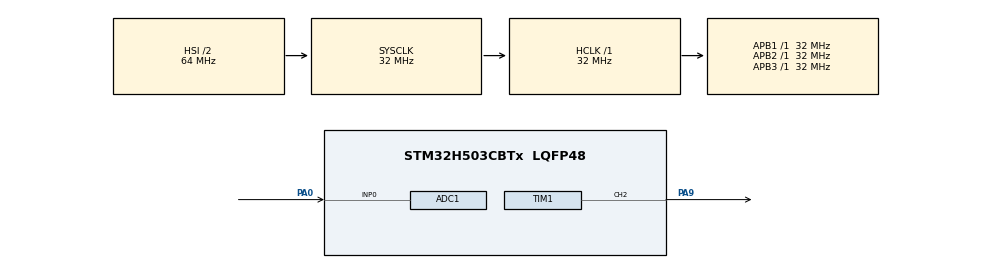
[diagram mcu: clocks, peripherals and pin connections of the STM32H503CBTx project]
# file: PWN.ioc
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ADC1.Channel-0\#ChannelRegularConversion=ADC_CHANNEL_0
ADC1.MonitoredBy-0\#ChannelRegularConversion=__NULL
ADC1.NbrOfConversionFlag=1
ADC1.OffsetNumber-0\#ChannelRegularConversion=ADC_OFFSET_NONE
ADC1.Rank-0\#ChannelRegularConversion=1
ADC1.SamplingTime-0\#ChannelRegularConversion=ADC_SAMPLETIME_2CYCLES_5
ADC1.master=1
Mcu.Family=STM32H5
Mcu.Name=STM32H503CBTx
Mcu.Package=LQFP48
NVIC.PriorityGroup=NVIC_PRIORITYGROUP_4
PA0.Signal=ADCx_INP0
PA9.Signal=S_TIM1_CH2
PH0-OSC_IN(PH0).Mode=HSE-External-Oscillator
PH0-OSC_IN(PH0).Signal=RCC_OSC_IN
PH1-OSC_OUT(PH1).Mode=HSE-External-Oscillator
PH1-OSC_OUT(PH1).Signal=RCC_OSC_OUT
ProjectManager.HeapSize=0x200
ProjectManager.StackSize=0x400
ProjectManager.TargetToolchain=STM32CubeIDE
RCC.ADCFreq_Value=32000000
RCC.AHBFreq_Value=32000000
RCC.APB1Freq_Value=32000000
RCC.APB1TimFreq_Value=32000000
RCC.APB2Freq_Value=32000000
RCC.APB2TimFreq_Value=32000000
RCC.APB3Freq_Value=32000000
RCC.CSI_VALUE=4000000
RCC.CortexFreq_Value=32000000
RCC.EPOD_VALUE=4000000
RCC.HCLKFreq_Value=32000000
RCC.HSE_VALUE=25000000
RCC.HSI48_VALUE=48000000
RCC.HSI_VALUE=64000000
RCC.LSE_VALUE=32768
RCC.LSIRC_VALUE=32000
RCC.SYSCLKFreq_VALUE=32000000
RCC.USBFreq_Value=48000000
RCC.VCOOutputFreq_Value=516000000
SH.ADCx_INP0.0=ADC1_INP0,IN0-Single-Ended
SH.S_TIM1_CH2.0=TIM1_CH2,PWM Generation2 CH2
TIM1.Channel-PWM\ Generation2\ CH2=TIM_CHANNEL_2
VP_BOOTPATH_VS_BOOTPATH.Mode=BP_Activate
VP_CORTEX_M33_NS_VS_Hclk.Mode=Hclk_Mode
VP_MEMORYMAP_VS_MEMORYMAP.Mode=CurAppReg
VP_PWR_VS_LPOM.Mode=PowerOptimisation
VP_PWR_VS_SECSignals.Mode=Security/Privilege
board=custom

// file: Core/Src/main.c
/* USER CODE BEGIN Header */
/**
  ******************************************************************************
  * @file           : main.c
  * @brief          : Main program body
  ******************************************************************************
  * @attention
  *
  * Copyright (c) 2025 STMicroelectronics.
  * All rights reserved.
  *
  * This software is licensed under terms that can be found in the LICENSE file
  * in the root directory of this software component.
  * If no LICENSE file comes with this software, it is provided AS-IS.
  *
  ******************************************************************************
  */
/* USER CODE END Header */
#include "main.h"

ADC_HandleTypeDef hadc1;

TIM_HandleTypeDef htim1;

/* USER CODE BEGIN PV */
uint32_t adc_value = 0;     // Значение АЦП (0-4095)
uint16_t pwm_duty = 0;      // Скважность ШИМ (0-999)
/* USER CODE END PV */

void SystemClock_Config(void);
static void MX_GPIO_Init(void);
static void MX_ADC1_Init(void);
static void MX_TIM1_Init(void);

int main(void)
{

  /* MCU Configuration--------------------------------------------------------*/

  /* Reset of all peripherals, Initializes the Flash interface and the Systick. */
  HAL_Init();

  /* Configure the system clock */
  SystemClock_Config();

  /* Initialize all configured peripherals */
  MX_GPIO_Init();
  MX_ADC1_Init();
  MX_TIM1_Init();
  /* USER CODE BEGIN 2 */

  HAL_TIM_PWM_Start(&htim1, TIM_CHANNEL_2);

  // Запускаем АЦП
  HAL_ADC_Start(&hadc1);

  /* USER CODE END 2 */

  /* Infinite loop */
  while (1)
  {

    /* USER CODE BEGIN 3 */

    HAL_ADC_Start(&hadc1);

    if (HAL_ADC_PollForConversion(&hadc1, 10) == HAL_OK)
    {
      //  значение АЦП
      adc_value = HAL_ADC_GetValue(&hadc1);

      //  АЦП (0-4095) в ШИМ (0-65535)
      pwm_duty = (adc_value * 65535) / 4095;

      //  скважность ШИМ
      __HAL_TIM_SET_COMPARE(&htim1, TIM_CHANNEL_2, pwm_duty);
    }

    HAL_Delay(10);
  }
  /* USER CODE END 3 */
}

void SystemClock_Config(void)
{
  RCC_OscInitTypeDef RCC_OscInitStruct = {0};
  RCC_ClkInitTypeDef RCC_ClkInitStruct = {0};

  /** Configure the main internal regulator output voltage
  */
  __HAL_PWR_VOLTAGESCALING_CONFIG(PWR_REGULATOR_VOLTAGE_SCALE3);

  while(!__HAL_PWR_GET_FLAG(PWR_FLAG_VOSRDY)) {}

  /** Initializes the RCC Oscillators according to the specified parameters
  * in the RCC_OscInitTypeDef structure.
  */
  RCC_OscInitStruct.OscillatorType = RCC_OSCILLATORTYPE_HSI;
  RCC_OscInitStruct.HSIState = RCC_HSI_ON;
  RCC_OscInitStruct.HSIDiv = RCC_HSI_DIV2;
  RCC_OscInitStruct.HSICalibrationValue = RCC_HSICALIBRATION_DEFAULT;
  RCC_OscInitStruct.PLL.PLLState = RCC_PLL_NONE;
  if (HAL_RCC_OscConfig(&RCC_OscInitStruct) != HAL_OK)
  {
    Error_Handler();
  }

  /** Initializes the CPU, AHB and APB buses clocks
  */
  RCC_ClkInitStruct.ClockType = RCC_CLOCKTYPE_HCLK|RCC_CLOCKTYPE_SYSCLK
                              |RCC_CLOCKTYPE_PCLK1|RCC_CLOCKTYPE_PCLK2
                              |RCC_CLOCKTYPE_PCLK3;
  RCC_ClkInitStruct.SYSCLKSource = RCC_SYSCLKSOURCE_HSI;
  RCC_ClkInitStruct.AHBCLKDivider = RCC_SYSCLK_DIV1;
  RCC_ClkInitStruct.APB1CLKDivider = RCC_HCLK_DIV1;
  RCC_ClkInitStruct.APB2CLKDivider = RCC_HCLK_DIV1;
  RCC_ClkInitStruct.APB3CLKDivider = RCC_HCLK_DIV1;

  if (HAL_RCC_ClockConfig(&RCC_ClkInitStruct, FLASH_LATENCY_1) != HAL_OK)
  {
    Error_Handler();
  }

  /** Configure the programming delay
  */
  __HAL_FLASH_SET_PROGRAM_DELAY(FLASH_PROGRAMMING_DELAY_0);
}

static void MX_ADC1_Init(void)
{

  ADC_ChannelConfTypeDef sConfig = {0};

  /** Common config
  */
  hadc1.Instance = ADC1;
  hadc1.Init.ClockPrescaler = ADC_CLOCK_ASYNC_DIV1;
  hadc1.Init.Resolution = ADC_RESOLUTION_12B;
  hadc1.Init.DataAlign = ADC_DATAALIGN_RIGHT;
  hadc1.Init.ScanConvMode = ADC_SCAN_DISABLE;
  hadc1.Init.EOCSelection = ADC_EOC_SINGLE_CONV;
  hadc1.Init.LowPowerAutoWait = DISABLE;
  hadc1.Init.ContinuousConvMode = DISABLE;
  hadc1.Init.NbrOfConversion = 1;
  hadc1.Init.DiscontinuousConvMode = DISABLE;
  hadc1.Init.ExternalTrigConv = ADC_SOFTWARE_START;
  hadc1.Init.ExternalTrigConvEdge = ADC_EXTERNALTRIGCONVEDGE_NONE;
  hadc1.Init.DMAContinuousRequests = DISABLE;
  hadc1.Init.SamplingMode = ADC_SAMPLING_MODE_NORMAL;
  hadc1.Init.Overrun = ADC_OVR_DATA_PRESERVED;
  hadc1.Init.OversamplingMode = DISABLE;
  if (HAL_ADC_Init(&hadc1) != HAL_OK)
  {
    Error_Handler();
  }

  /** Configure Regular Channel
  */
  sConfig.Channel = ADC_CHANNEL_0;
  sConfig.Rank = ADC_REGULAR_RANK_1;
  sConfig.SamplingTime = ADC_SAMPLETIME_2CYCLES_5;
  sConfig.SingleDiff = ADC_SINGLE_ENDED;
  sConfig.OffsetNumber = ADC_OFFSET_NONE;
  sConfig.Offset = 0;
  if (HAL_ADC_ConfigChannel(&hadc1, &sConfig) != HAL_OK)
  {
    Error_Handler();
  }

}

static void MX_TIM1_Init(void)
{

  TIM_MasterConfigTypeDef sMasterConfig = {0};
  TIM_OC_InitTypeDef sConfigOC = {0};
  TIM_BreakDeadTimeConfigTypeDef sBreakDeadTimeConfig = {0};

  htim1.Instance = TIM1;
  htim1.Init.Prescaler = 0;
  htim1.Init.CounterMode = TIM_COUNTERMODE_UP;
  htim1.Init.Period = 65535;
  htim1.Init.ClockDivision = TIM_CLOCKDIVISION_DIV1;
  htim1.Init.RepetitionCounter = 0;
  htim1.Init.AutoReloadPreload = TIM_AUTORELOAD_PRELOAD_DISABLE;
  if (HAL_TIM_PWM_Init(&htim1) != HAL_OK)
  {
    Error_Handler();
  }
  sMasterConfig.MasterOutputTrigger = TIM_TRGO_RESET;
  sMasterConfig.MasterOutputTrigger2 = TIM_TRGO2_RESET;
  sMasterConfig.MasterSlaveMode = TIM_MASTERSLAVEMODE_DISABLE;
  if (HAL_TIMEx_MasterConfigSynchronization(&htim1, &sMasterConfig) != HAL_OK)
  {
    Error_Handler();
  }
  sConfigOC.OCMode = TIM_OCMODE_PWM1;
  sConfigOC.Pulse = 0;
  sConfigOC.OCPolarity = TIM_OCPOLARITY_HIGH;
  sConfigOC.OCNPolarity = TIM_OCNPOLARITY_HIGH;
  sConfigOC.OCFastMode = TIM_OCFAST_DISABLE;
  sConfigOC.OCIdleState = TIM_OCIDLESTATE_RESET;
  sConfigOC.OCNIdleState = TIM_OCNIDLESTATE_RESET;
  if (HAL_TIM_PWM_ConfigChannel(&htim1, &sConfigOC, TIM_CHANNEL_2) != HAL_OK)
  {
    Error_Handler();
  }
  sBreakDeadTimeConfig.OffStateRunMode = TIM_OSSR_DISABLE;
  sBreakDeadTimeConfig.OffStateIDLEMode = TIM_OSSI_DISABLE;
  sBreakDeadTimeConfig.LockLevel = TIM_LOCKLEVEL_OFF;
  sBreakDeadTimeConfig.DeadTime = 0;
  sBreakDeadTimeConfig.BreakState = TIM_BREAK_DISABLE;
  sBreakDeadTimeConfig.BreakPolarity = TIM_BREAKPOLARITY_HIGH;
  sBreakDeadTimeConfig.BreakFilter = 0;
  sBreakDeadTimeConfig.BreakAFMode = TIM_BREAK_AFMODE_INPUT;
  sBreakDeadTimeConfig.Break2State = TIM_BREAK2_DISABLE;
  sBreakDeadTimeConfig.Break2Polarity = TIM_BREAK2POLARITY_HIGH;
  sBreakDeadTimeConfig.Break2Filter = 0;
  sBreakDeadTimeConfig.Break2AFMode = TIM_BREAK_AFMODE_INPUT;
  sBreakDeadTimeConfig.AutomaticOutput = TIM_AUTOMATICOUTPUT_DISABLE;
  if (HAL_TIMEx_ConfigBreakDeadTime(&htim1, &sBreakDeadTimeConfig) != HAL_OK)
  {
    Error_Handler();
  }
  HAL_TIM_MspPostInit(&htim1);

}

static void MX_GPIO_Init(void)
{

  /* GPIO Ports Clock Enable */
  __HAL_RCC_GPIOH_CLK_ENABLE();
  __HAL_RCC_GPIOA_CLK_ENABLE();

}

void Error_Handler(void)
{
  __disable_irq();
  while (1)
  {
  }
}
